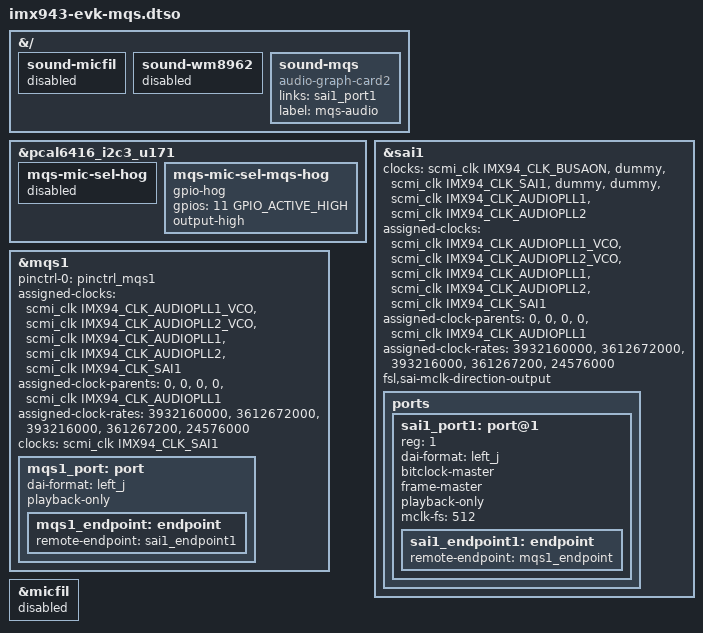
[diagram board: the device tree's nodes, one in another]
// SPDX-License-Identifier: (GPL-2.0+ OR MIT)
/*
 * Copyright 2025 NXP
 */

#include <dt-bindings/gpio/gpio.h>
#include "imx94-clock.h"

/dts-v1/;
/plugin/;

&{/} {
	sound-micfil {
		status = "disabled";
	};

	sound-wm8962 {
		status = "disabled";
	};

	sound-mqs {
		compatible = "audio-graph-card2";
		links = <&sai1_port1>;
		label = "mqs-audio";
	};
};

/*
 * mqs-mic-sel-hog have property 'output-low', dt overlay don't support
 * /delete-property/. Both 'output-low' and 'output-high' will be exist
 * under hog nodes if overlay file set 'output-high'. Workaround is
 * disable the hog and create new hog with 'output-high'.
 */
&pcal6416_i2c3_u171 {

	mqs-mic-sel-hog {
		status = "disabled";
	};

	mqs-mic-sel-mqs-hog {
		gpio-hog;
		gpios = <11 GPIO_ACTIVE_HIGH>;
		output-high;
	};
};

&sai1 {
	clocks = <&scmi_clk IMX94_CLK_BUSAON>, <&dummy>,
		 <&scmi_clk IMX94_CLK_SAI1>, <&dummy>,
		 <&dummy>, <&scmi_clk IMX94_CLK_AUDIOPLL1>,
		 <&scmi_clk IMX94_CLK_AUDIOPLL2>;
	clock-names = "bus", "mclk0", "mclk1", "mclk2", "mclk3", "pll8k", "pll11k";
	assigned-clocks = <&scmi_clk IMX94_CLK_AUDIOPLL1_VCO>,
			<&scmi_clk IMX94_CLK_AUDIOPLL2_VCO>,
			<&scmi_clk IMX94_CLK_AUDIOPLL1>,
			<&scmi_clk IMX94_CLK_AUDIOPLL2>,
			<&scmi_clk IMX94_CLK_SAI1>;
	assigned-clock-parents = <0>, <0>, <0>, <0>,
			<&scmi_clk IMX94_CLK_AUDIOPLL1>;
	assigned-clock-rates = <3932160000>,
			<3612672000>, <393216000>,
			<361267200>, <24576000>;
	fsl,sai-mclk-direction-output;
	status = "okay";

	ports {
		#address-cells = <1>;
		#size-cells = <0>;

		sai1_port1: port@1 {
			reg = <1>;
			dai-format = "left_j";
			bitclock-master;
			frame-master;
			playback-only;
			mclk-fs = <512>;

			sai1_endpoint1: endpoint {
				remote-endpoint = <&mqs1_endpoint>;
			};
		};
	};
};

&mqs1 {
	pinctrl-names = "default";
	pinctrl-0 = <&pinctrl_mqs1>;
	assigned-clocks = <&scmi_clk IMX94_CLK_AUDIOPLL1_VCO>,
			<&scmi_clk IMX94_CLK_AUDIOPLL2_VCO>,
			<&scmi_clk IMX94_CLK_AUDIOPLL1>,
			<&scmi_clk IMX94_CLK_AUDIOPLL2>,
			<&scmi_clk IMX94_CLK_SAI1>;
	assigned-clock-parents = <0>, <0>, <0>, <0>,
			<&scmi_clk IMX94_CLK_AUDIOPLL1>;
	assigned-clock-rates = <3932160000>,
			<3612672000>, <393216000>,
			<361267200>, <24576000>;
	clocks = <&scmi_clk IMX94_CLK_SAI1>;
	clock-names = "mclk";
	#sound-dai-cells = <0>;
	status = "okay";

	mqs1_port: port {
		dai-format = "left_j";
		playback-only;

		mqs1_endpoint: endpoint {
			remote-endpoint = <&sai1_endpoint1>;
		};
	};
};

&micfil {
	status = "disabled";
};
